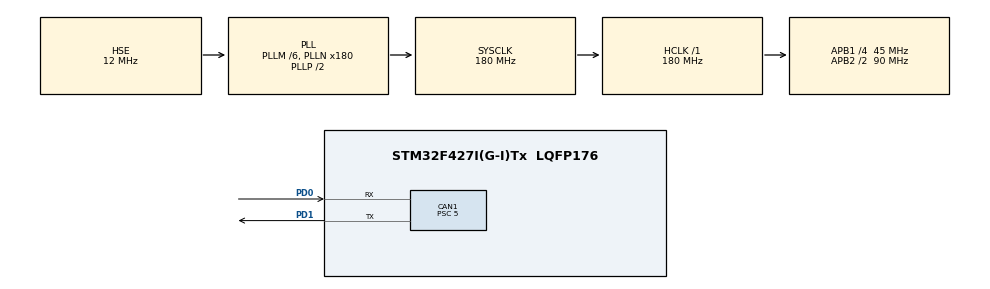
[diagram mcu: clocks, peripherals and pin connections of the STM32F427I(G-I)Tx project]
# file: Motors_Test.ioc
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CAN1.BS1=CAN_BS1_2TQ
CAN1.BS2=CAN_BS2_6TQ
CAN1.CalculateBaudRate=1000000
CAN1.CalculateTimeBit=1000
CAN1.CalculateTimeQuantum=111.11111111111111
CAN1.Prescaler=5
CAN1.SJW=CAN_SJW_1TQ
FREERTOS.Tasks01=defaultTask,24,128,StartDefaultTask,Default,NULL,Dynamic,NULL,NULL;MotorControl,24,128,MotorControlThread,As external,NULL,Static,MotorControlTasBuffer,MotorControlTasControlBlock;CANManagerSend,24,128,CANManagerSendThread,As external,NULL,Static,CANManagerSendTBuffer,CANManagerSendTControlBlock
Mcu.Family=STM32F4
Mcu.Name=STM32F427I(G-I)Tx
Mcu.Package=LQFP176
NVIC.CAN1_RX0_IRQn=true\:5\:0\:false\:false\:true\:true\:true\:true\:true
NVIC.CAN1_RX1_IRQn=true\:5\:0\:false\:false\:true\:true\:true\:true\:true
NVIC.CAN1_SCE_IRQn=true\:5\:0\:false\:false\:true\:true\:true\:true\:true
NVIC.CAN1_TX_IRQn=true\:5\:0\:false\:false\:true\:true\:true\:true\:true
NVIC.PriorityGroup=NVIC_PRIORITYGROUP_4
NVIC.TIM8_TRG_COM_TIM14_IRQn=true\:15\:0\:false\:false\:true\:false\:false\:true\:true
NVIC.TimeBase=TIM8_TRG_COM_TIM14_IRQn
NVIC.TimeBaseIP=TIM14
PA13.Mode=Serial_Wire
PA13.Signal=SYS_JTMS-SWDIO
PA14.Mode=Serial_Wire
PA14.Signal=SYS_JTCK-SWCLK
PD0.Mode=CAN_Activate
PD0.Signal=CAN1_RX
PD1.Mode=CAN_Activate
PD1.Signal=CAN1_TX
PH0/OSC_IN.Mode=HSE-External-Oscillator
PH0/OSC_IN.Signal=RCC_OSC_IN
PH1/OSC_OUT.Mode=HSE-External-Oscillator
PH1/OSC_OUT.Signal=RCC_OSC_OUT
ProjectManager.HeapSize=0x200
ProjectManager.StackSize=0x400
ProjectManager.TargetToolchain=CMake
RCC.48MHZClocksFreq_Value=90000000
RCC.AHBFreq_Value=180000000
RCC.APB1CLKDivider=RCC_HCLK_DIV4
RCC.APB1Freq_Value=45000000
RCC.APB1TimFreq_Value=90000000
RCC.APB2CLKDivider=RCC_HCLK_DIV2
RCC.APB2Freq_Value=90000000
RCC.APB2TimFreq_Value=180000000
RCC.CortexFreq_Value=180000000
RCC.HCLKFreq_Value=180000000
RCC.HSE_VALUE=12000000
RCC.HSI_VALUE=16000000
RCC.LSE_VALUE=32768
RCC.PLLM=6
RCC.PLLN=180
RCC.PLLSourceVirtual=RCC_PLLSOURCE_HSE
RCC.SYSCLKFreq_VALUE=180000000
RCC.SYSCLKSource=RCC_SYSCLKSOURCE_PLLCLK
RCC.VCOOutputFreq_Value=360000000
VP_FREERTOS_VS_CMSIS_V2.Mode=CMSIS_V2
VP_SYS_VS_tim14.Mode=TIM14
board=custom

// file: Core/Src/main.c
/* USER CODE BEGIN Header */
/**
  ******************************************************************************
  * @file           : main.c
  * @brief          : Main program body
  ******************************************************************************
  * @attention
  *
  * Copyright (c) 2025 STMicroelectronics.
  * All rights reserved.
  *
  * This software is licensed under terms that can be found in the LICENSE file
  * in the root directory of this software component.
  * If no LICENSE file comes with this software, it is provided AS-IS.
  *
  ******************************************************************************
  */
/* USER CODE END Header */
#include "main.h"
#include "cmsis_os.h"
#include "can.h"
#include "gpio.h"

/* USER CODE BEGIN Includes */
#include "string.h"
/* USER CODE END Includes */

void SystemClock_Config(void);
void MX_FREERTOS_Init(void);

/* USER CODE BEGIN 0 */

void CAN_Config(void)
{
  CAN_FilterTypeDef  sFilterConfig;

  /* Configure the CAN Filter */
  sFilterConfig.FilterBank = 0;                      // 过滤器编号，使用一个CAN，则可选0-13；使用两个CAN可选0-27
  sFilterConfig.FilterMode = CAN_FILTERMODE_IDMASK;  // 过滤器模式，掩码模式或列表模式
  sFilterConfig.FilterScale = CAN_FILTERSCALE_32BIT; // 过滤器位宽
  sFilterConfig.FilterIdHigh = 0x0000;               // 过滤器验证码ID高16位，0-0xFFFF
  sFilterConfig.FilterIdLow = 0x0000;                // 过滤器验证码ID低16位，0-0xFFFF
  sFilterConfig.FilterMaskIdHigh = 0x0000;           // 过滤器掩码ID高16位，0-0xFFFF
  sFilterConfig.FilterMaskIdLow = 0x0000;            // 过滤器掩码ID低16位，0-0xFFFF
  sFilterConfig.FilterFIFOAssignment = CAN_FilterFIFO0; // FIFOx，0或1
  sFilterConfig.FilterActivation = ENABLE;           // 使能过滤器
  sFilterConfig.SlaveStartFilterBank = 14;           // 从过滤器编号，0-27，对于单CAN实例该参数没有意义

  if (HAL_CAN_ConfigFilter(&hcan1, &sFilterConfig) != HAL_OK)
  {
    /* Filter configuration Error */
  }

  /* Start the CAN peripheral */
  if (HAL_CAN_Start(&hcan1) != HAL_OK)
  {
    /* Start Error */
  }

  /* Activate CAN RX notification */
  if (HAL_CAN_ActivateNotification(&hcan1, CAN_IT_RX_FIFO0_MSG_PENDING) != HAL_OK)
  {
    /* Notification Error */
  }
  //__HAL_CAN_ENABLE_IT(&hcan1, CAN_IT_RX_FIFO0_MSG_PENDING);
  //__HAL_CAN_ENABLE_IT(&hcan1, CAN_IT_RX_FIFO1_MSG_PENDING);
}

// struct PID {
//   float kp;
//   float ki;
//   float kd;
//   float integral;
//   float last_error;
//   float error;
//   float output;
//   float i_max;
//   float output_max;
// };

// struct DJIMotor {
//   enum {
//     MOTOR_2006,
//     MOTOR_3508,
//     MOTOR_GM6020,
//   } motor_id;
//   int16_t motor_speed;//单位rpm
//   uint16_t motor_raw_angle;
//   float motor_angle;//角度制
//   int16_t motor_current;
//   uint8_t  temp;

//   int16_t ref_motor_speed;
//   uint16_t ref_motor_raw_angle;
//   float ref_motor_angle;
//   int16_t ref_motor_current;

//   int16_t output_value;

//   struct PID pid;

// };

// struct DJIMotor test_motor = {
//   .motor_id = MOTOR_3508,
//   .motor_speed = 0,
//   .motor_raw_angle = 0,
//   .motor_angle = 0.0f,
//   .motor_current = 0,
//   .temp = 0,

//   .ref_motor_speed = 0,
//   .ref_motor_raw_angle = 0,
//   .ref_motor_angle = 0.0f,
//   .ref_motor_current = 0,
//   .output_value = 0
// };

// uint8_t CAN_Send_Msg(uint16_t output , uint8_t len)
// {
//   uint8_t message[8];
//   uint32_t TxMailbox;
//   CAN_TxHeaderTypeDef CAN_TxHeader;

//   // 设置发送参数
//   CAN_TxHeader.StdId = 0x200;                 // 标准标识符(12bit)
//   //CAN_TxHeader.ExtId = 0x00;                 // 扩展标识符(29bit)
//   CAN_TxHeader.IDE = CAN_ID_STD;             // 使用标准帧
//   CAN_TxHeader.RTR = CAN_RTR_DATA;           // 数据帧
//   CAN_TxHeader.DLC = 0x08;                    // 发送长度
//   //CAN_TxHeader.TransmitGlobalTime = DISABLE;//关闭can的时间触发通信模式

//   // 装载数据
//   memset(message, 0, sizeof(message));
//   message[0] = (output >> 8) & 0xFF;
//   message[1] = output & 0xFF;

//   // 发送CAN消息
//   if(HAL_CAN_AddTxMessage(&hcan1, &CAN_TxHeader, message, &TxMailbox) != HAL_OK)
//   {
//     return 1;
//   }

//   return 0;
// }

// void HAL_CAN_RxFifo0MsgPendingCallback(CAN_HandleTypeDef *hcan)
// {// 收到CAN数据会触发接收中断，进入该回调函数
//   uint8_t RxData[8];
//   CAN_RxHeaderTypeDef CAN_RxHeader;

//   if(HAL_CAN_GetRxMessage(hcan, CAN_RX_FIFO0, &CAN_RxHeader, RxData) != HAL_OK)
//   {
//     while(1) {};
//   }

//   if(hcan==&hcan1) // 只处理CAN1
//   {
//     // 处理CAN1接收到的数据
//     switch (CAN_RxHeader.StdId) // 标准标识符
//     {
//       case 0x201:
//         // 处理ID为0x201的消息
//         test_motor.motor_raw_angle = (RxData[0] << 8) | RxData[1];
//         test_motor.motor_angle = (float)test_motor.motor_raw_angle/8191.f*360.f;
//         test_motor.motor_speed = (RxData[2] << 8) | RxData[3];
//         test_motor.motor_current = (RxData[4] << 8) | RxData[5];
//         test_motor.temp = RxData[6];
//         break;
//       default:
//         break;
//     }
//   }
// }

// uint16_t PID_Calc(struct PID *pid) {
//   float derror = pid->error - pid->last_error;
//   pid->integral += pid->error;

//   if (pid->integral > pid->i_max) {
//     pid->integral = pid->i_max;
//   } else if (pid->integral < -pid->i_max) {
//     pid->integral = -pid->i_max;
//   }

//   pid->output = pid->kp * pid->error + pid->ki * pid->integral + pid->kd * derror;
//   if (pid->output > pid->output_max) {
//     pid->output = pid->output_max;
//   } else if (pid->output < -pid->output_max) {
//     pid->output = -pid->output_max;
//   }

//   pid->last_error = pid->error;
//   return (int16_t)pid->output;
// }

/* USER CODE END 0 */

int main(void)
{

  /* MCU Configuration--------------------------------------------------------*/

  /* Reset of all peripherals, Initializes the Flash interface and the Systick. */
  HAL_Init();

  /* Configure the system clock */
  SystemClock_Config();

  /* Initialize all configured peripherals */
  MX_GPIO_Init();
  MX_CAN1_Init();
  /* USER CODE BEGIN 2 */
  CAN_Config(); // 配置CAN
  /* USER CODE END 2 */

  /* Init scheduler */
  osKernelInitialize();  /* Call init function for freertos objects (in cmsis_os2.c) */
  MX_FREERTOS_Init();

  /* Start scheduler */
  osKernelStart();

  /* We should never get here as control is now taken by the scheduler */

  /* Infinite loop */
  while (1)
  {

  }
}

void SystemClock_Config(void)
{
  RCC_OscInitTypeDef RCC_OscInitStruct = {0};
  RCC_ClkInitTypeDef RCC_ClkInitStruct = {0};

  /** Configure the main internal regulator output voltage
  */
  __HAL_RCC_PWR_CLK_ENABLE();
  __HAL_PWR_VOLTAGESCALING_CONFIG(PWR_REGULATOR_VOLTAGE_SCALE1);

  /** Initializes the RCC Oscillators according to the specified parameters
  * in the RCC_OscInitTypeDef structure.
  */
  RCC_OscInitStruct.OscillatorType = RCC_OSCILLATORTYPE_HSE;
  RCC_OscInitStruct.HSEState = RCC_HSE_ON;
  RCC_OscInitStruct.PLL.PLLState = RCC_PLL_ON;
  RCC_OscInitStruct.PLL.PLLSource = RCC_PLLSOURCE_HSE;
  RCC_OscInitStruct.PLL.PLLM = 6;
  RCC_OscInitStruct.PLL.PLLN = 180;
  RCC_OscInitStruct.PLL.PLLP = RCC_PLLP_DIV2;
  RCC_OscInitStruct.PLL.PLLQ = 4;
  if (HAL_RCC_OscConfig(&RCC_OscInitStruct) != HAL_OK)
  {
    Error_Handler();
  }

  /** Activate the Over-Drive mode
  */
  if (HAL_PWREx_EnableOverDrive() != HAL_OK)
  {
    Error_Handler();
  }

  /** Initializes the CPU, AHB and APB buses clocks
  */
  RCC_ClkInitStruct.ClockType = RCC_CLOCKTYPE_HCLK|RCC_CLOCKTYPE_SYSCLK
                              |RCC_CLOCKTYPE_PCLK1|RCC_CLOCKTYPE_PCLK2;
  RCC_ClkInitStruct.SYSCLKSource = RCC_SYSCLKSOURCE_PLLCLK;
  RCC_ClkInitStruct.AHBCLKDivider = RCC_SYSCLK_DIV1;
  RCC_ClkInitStruct.APB1CLKDivider = RCC_HCLK_DIV4;
  RCC_ClkInitStruct.APB2CLKDivider = RCC_HCLK_DIV2;

  if (HAL_RCC_ClockConfig(&RCC_ClkInitStruct, FLASH_LATENCY_5) != HAL_OK)
  {
    Error_Handler();
  }
}

void HAL_TIM_PeriodElapsedCallback(TIM_HandleTypeDef *htim)
{
  if (htim->Instance == TIM14)
  {
    HAL_IncTick();
  }
}

void Error_Handler(void)
{
  __disable_irq();
  while (1)
  {
  }
}

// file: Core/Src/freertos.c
/* USER CODE BEGIN Header */
/**
  ******************************************************************************
  * File Name          : freertos.c
  * Description        : Code for freertos applications
  ******************************************************************************
  * @attention
  *
  * Copyright (c) 2025 STMicroelectronics.
  * All rights reserved.
  *
  * This software is licensed under terms that can be found in the LICENSE file
  * in the root directory of this software component.
  * If no LICENSE file comes with this software, it is provided AS-IS.
  *
  ******************************************************************************
  */
/* USER CODE END Header */

#include "FreeRTOS.h"
#include "task.h"
#include "main.h"
#include "cmsis_os.h"

typedef StaticTask_t osStaticThreadDef_t;

/* Definitions for defaultTask */
osThreadId_t defaultTaskHandle;
const osThreadAttr_t defaultTask_attributes = {
  .name = "defaultTask",
  .stack_size = 128 * 4,
  .priority = (osPriority_t) osPriorityNormal,
};
/* Definitions for MotorControl */
osThreadId_t MotorControlHandle;
uint32_t MotorControlTasBuffer[ 128 ];
osStaticThreadDef_t MotorControlTasControlBlock;
const osThreadAttr_t MotorControl_attributes = {
  .name = "MotorControl",
  .cb_mem = &MotorControlTasControlBlock,
  .cb_size = sizeof(MotorControlTasControlBlock),
  .stack_mem = &MotorControlTasBuffer[0],
  .stack_size = sizeof(MotorControlTasBuffer),
  .priority = (osPriority_t) osPriorityNormal,
};
/* Definitions for CANManagerSend */
osThreadId_t CANManagerSendHandle;
uint32_t CANManagerSendTBuffer[ 128 ];
osStaticThreadDef_t CANManagerSendTControlBlock;
const osThreadAttr_t CANManagerSend_attributes = {
  .name = "CANManagerSend",
  .cb_mem = &CANManagerSendTControlBlock,
  .cb_size = sizeof(CANManagerSendTControlBlock),
  .stack_mem = &CANManagerSendTBuffer[0],
  .stack_size = sizeof(CANManagerSendTBuffer),
  .priority = (osPriority_t) osPriorityNormal,
};

void StartDefaultTask(void *argument);
extern void MotorControlThread(void *argument);
extern void CANManagerSendThread(void *argument);

void MX_FREERTOS_Init(void); /* (MISRA C 2004 rule 8.1) */

void MX_FREERTOS_Init(void) {

  /* Create the thread(s) */
  /* creation of defaultTask */
  defaultTaskHandle = osThreadNew(StartDefaultTask, NULL, &defaultTask_attributes);

  /* creation of MotorControl */
  MotorControlHandle = osThreadNew(MotorControlThread, NULL, &MotorControl_attributes);

  /* creation of CANManagerSend */
  CANManagerSendHandle = osThreadNew(CANManagerSendThread, NULL, &CANManagerSend_attributes);

}

void StartDefaultTask(void *argument)
{
  for(;;)
  {
    osDelay(1);
  }
}
